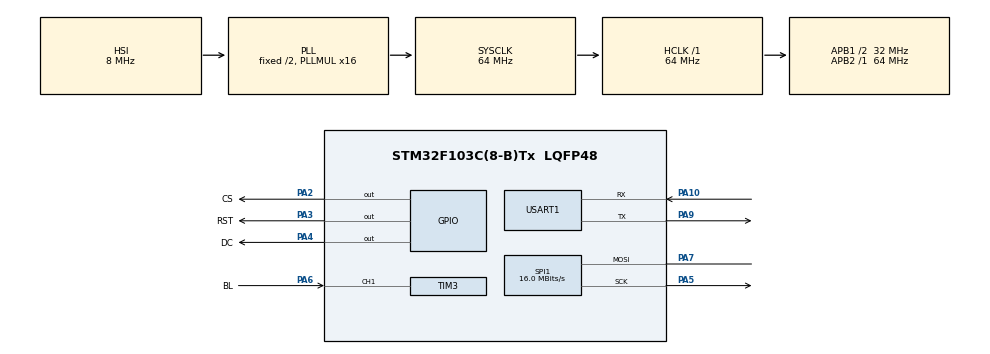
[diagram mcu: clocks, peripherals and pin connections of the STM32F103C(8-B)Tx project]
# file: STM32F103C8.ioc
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Dma.Request0=USART1_RX
Dma.Request1=USART1_TX
Dma.USART1_RX.0.Direction=DMA_PERIPH_TO_MEMORY
Dma.USART1_RX.0.Instance=DMA1_Channel5
Dma.USART1_RX.0.MemDataAlignment=DMA_MDATAALIGN_BYTE
Dma.USART1_RX.0.MemInc=DMA_MINC_ENABLE
Dma.USART1_RX.0.Mode=DMA_CIRCULAR
Dma.USART1_RX.0.PeriphDataAlignment=DMA_PDATAALIGN_BYTE
Dma.USART1_RX.0.PeriphInc=DMA_PINC_DISABLE
Dma.USART1_RX.0.Priority=DMA_PRIORITY_LOW
Dma.USART1_TX.1.Direction=DMA_MEMORY_TO_PERIPH
Dma.USART1_TX.1.Instance=DMA1_Channel4
Dma.USART1_TX.1.MemDataAlignment=DMA_MDATAALIGN_BYTE
Dma.USART1_TX.1.MemInc=DMA_MINC_ENABLE
Dma.USART1_TX.1.Mode=DMA_NORMAL
Dma.USART1_TX.1.PeriphDataAlignment=DMA_PDATAALIGN_BYTE
Dma.USART1_TX.1.PeriphInc=DMA_PINC_DISABLE
Dma.USART1_TX.1.Priority=DMA_PRIORITY_LOW
FREERTOS.Tasks01=defaultTask,0,128,StartDefaultTask,Default,NULL,Dynamic,NULL,NULL
Mcu.Family=STM32F1
Mcu.Name=STM32F103C(8-B)Tx
Mcu.Package=LQFP48
NVIC.DMA1_Channel4_IRQn=true\:5\:0\:false\:false\:true\:true\:false\:true\:true
NVIC.DMA1_Channel5_IRQn=true\:5\:0\:false\:false\:true\:true\:false\:true\:true
NVIC.PriorityGroup=NVIC_PRIORITYGROUP_4
PA10.Mode=Asynchronous
PA10.Signal=USART1_RX
PA13.Signal=SYS_JTMS-SWDIO
PA14.Signal=SYS_JTCK-SWCLK
PA2.GPIO_Label=CS
PA2.Signal=GPIO_Output
PA3.GPIO_Label=RST
PA3.Signal=GPIO_Output
PA4.GPIO_Label=DC
PA4.Signal=GPIO_Output
PA5.Mode=Simplex_Bidirectional_Master
PA5.Signal=SPI1_SCK
PA6.GPIO_Label=BL
PA6.Signal=S_TIM3_CH1
PA7.Mode=Simplex_Bidirectional_Master
PA7.Signal=SPI1_MOSI
PA9.Mode=Asynchronous
PA9.Signal=USART1_TX
ProjectManager.HeapSize=0x200
ProjectManager.StackSize=0x400
ProjectManager.TargetToolchain=Makefile
RCC.AHBFreq_Value=64000000
RCC.APB1CLKDivider=RCC_HCLK_DIV2
RCC.APB1Freq_Value=32000000
RCC.APB1TimFreq_Value=64000000
RCC.APB2Freq_Value=64000000
RCC.APB2TimFreq_Value=64000000
RCC.HCLKFreq_Value=64000000
RCC.PLLMUL=RCC_PLL_MUL16
RCC.SYSCLKFreq_VALUE=64000000
RCC.SYSCLKSource=RCC_SYSCLKSOURCE_PLLCLK
RCC.USBFreq_Value=64000000
SH.S_TIM3_CH1.0=TIM3_CH1,Input_Capture1_from_TI1
SPI1.BaudRatePrescaler=SPI_BAUDRATEPRESCALER_4
SPI1.CalculateBaudRate=16.0 MBits/s
SPI1.Direction=SPI_DIRECTION_1LINE
SPI1.Mode=SPI_MODE_MASTER
SPI1.VirtualType=VM_MASTER
TIM1.Prescaler=63
TIM3.AutoReloadPreload=TIM_AUTORELOAD_PRELOAD_ENABLE
TIM3.Channel-Input_Capture1_from_TI1=TIM_CHANNEL_1
TIM3.Period=32768
TIM3.Prescaler=63
USART1.VirtualMode=VM_ASYNC
VP_FREERTOS_VS_CMSIS_V1.Mode=CMSIS_V1
VP_SYS_VS_ND.Mode=No_Debug
VP_TIM1_VS_ClockSourceINT.Mode=Internal
board=custom

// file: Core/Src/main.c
/* USER CODE BEGIN Header */
/**
  ******************************************************************************
  * @file           : main.c
  * @brief          : Main program body
  ******************************************************************************
  * @attention
  *
  * Copyright (c) 2024 STMicroelectronics.
  * All rights reserved.
  *
  * This software is licensed under terms that can be found in the LICENSE file
  * in the root directory of this software component.
  * If no LICENSE file comes with this software, it is provided AS-IS.
  *
  ******************************************************************************
  */
/* USER CODE END Header */
#include "main.h"
#include "cmsis_os.h"
#include "dma.h"
#include "spi.h"
#include "tim.h"
#include "usart.h"
#include "gpio.h"

void SystemClock_Config(void);
void MX_FREERTOS_Init(void);

int main(void)
{

  /* MCU Configuration--------------------------------------------------------*/

  /* Reset of all peripherals, Initializes the Flash interface and the Systick. */
  HAL_Init();

  /* Configure the system clock */
  SystemClock_Config();

  /* Initialize all configured peripherals */
  MX_GPIO_Init();
  MX_DMA_Init();
  MX_TIM1_Init();
  MX_USART1_UART_Init();
  MX_SPI1_Init();
  MX_TIM3_Init();

  /* Call init function for freertos objects (in freertos.c) */
  MX_FREERTOS_Init();

  /* Start scheduler */
  osKernelStart();

  /* We should never get here as control is now taken by the scheduler */
  /* Infinite loop */
  while (1)
  {

  }
}

void SystemClock_Config(void)
{
  RCC_OscInitTypeDef RCC_OscInitStruct = {0};
  RCC_ClkInitTypeDef RCC_ClkInitStruct = {0};

  /** Initializes the RCC Oscillators according to the specified parameters
  * in the RCC_OscInitTypeDef structure.
  */
  RCC_OscInitStruct.OscillatorType = RCC_OSCILLATORTYPE_HSI;
  RCC_OscInitStruct.HSIState = RCC_HSI_ON;
  RCC_OscInitStruct.HSICalibrationValue = RCC_HSICALIBRATION_DEFAULT;
  RCC_OscInitStruct.PLL.PLLState = RCC_PLL_ON;
  RCC_OscInitStruct.PLL.PLLSource = RCC_PLLSOURCE_HSI_DIV2;
  RCC_OscInitStruct.PLL.PLLMUL = RCC_PLL_MUL16;
  if (HAL_RCC_OscConfig(&RCC_OscInitStruct) != HAL_OK)
  {
    Error_Handler();
  }

  /** Initializes the CPU, AHB and APB buses clocks
  */
  RCC_ClkInitStruct.ClockType = RCC_CLOCKTYPE_HCLK|RCC_CLOCKTYPE_SYSCLK
                              |RCC_CLOCKTYPE_PCLK1|RCC_CLOCKTYPE_PCLK2;
  RCC_ClkInitStruct.SYSCLKSource = RCC_SYSCLKSOURCE_PLLCLK;
  RCC_ClkInitStruct.AHBCLKDivider = RCC_SYSCLK_DIV1;
  RCC_ClkInitStruct.APB1CLKDivider = RCC_HCLK_DIV2;
  RCC_ClkInitStruct.APB2CLKDivider = RCC_HCLK_DIV1;

  if (HAL_RCC_ClockConfig(&RCC_ClkInitStruct, FLASH_LATENCY_2) != HAL_OK)
  {
    Error_Handler();
  }
}

void Error_Handler(void)
{
  __disable_irq();
  while (1)
  {
  }
}

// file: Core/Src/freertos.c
/* USER CODE BEGIN Header */
/**
  ******************************************************************************
  * File Name          : freertos.c
  * Description        : Code for freertos applications
  ******************************************************************************
  * @attention
  *
  * Copyright (c) 2024 STMicroelectronics.
  * All rights reserved.
  *
  * This software is licensed under terms that can be found in the LICENSE file
  * in the root directory of this software component.
  * If no LICENSE file comes with this software, it is provided AS-IS.
  *
  ******************************************************************************
  */
/* USER CODE END Header */

#include "FreeRTOS.h"
#include "task.h"
#include "main.h"
#include "cmsis_os.h"

/* USER CODE BEGIN Includes */
#include "common.h"
/* USER CODE END Includes */

osThreadId defaultTaskHandle;

void StartDefaultTask(void const * argument);

void MX_FREERTOS_Init(void); /* (MISRA C 2004 rule 8.1) */

/* GetIdleTaskMemory prototype (linked to static allocation support) */
void vApplicationGetIdleTaskMemory( StaticTask_t **ppxIdleTaskTCBBuffer, StackType_t **ppxIdleTaskStackBuffer, uint32_t *pulIdleTaskStackSize );

/* USER CODE BEGIN GET_IDLE_TASK_MEMORY */
static StaticTask_t xIdleTaskTCBBuffer;
static StackType_t xIdleStack[configMINIMAL_STACK_SIZE];

void vApplicationGetIdleTaskMemory( StaticTask_t **ppxIdleTaskTCBBuffer, StackType_t **ppxIdleTaskStackBuffer, uint32_t *pulIdleTaskStackSize )
{
  *ppxIdleTaskTCBBuffer = &xIdleTaskTCBBuffer;
  *ppxIdleTaskStackBuffer = &xIdleStack[0];
  *pulIdleTaskStackSize = configMINIMAL_STACK_SIZE;
  /* place for user code */
}
/* USER CODE END GET_IDLE_TASK_MEMORY */

void MX_FREERTOS_Init(void) {

  /* Create the thread(s) */
  /* definition and creation of defaultTask */
  osThreadDef(defaultTask, StartDefaultTask, osPriorityNormal, 0, 128);
  defaultTaskHandle = osThreadCreate(osThread(defaultTask), NULL);

}

void StartDefaultTask(void const * argument)
{
  /* USER CODE BEGIN StartDefaultTask */
  //64x48方形大排线lcd
  printf(" init\n");

  HAL_TIM_PWM_Start(&htim1, TIM_CHANNEL_1);
  __HAL_TIM_SET_COMPARE(&htim1, TIM_CHANNEL_1, 50);

  lcd_init();
  lcd_test_display();
  /* Infinite loop */
  for(;;)
  {
    vTaskDelay(100);
  }
  /* USER CODE END StartDefaultTask */
}
